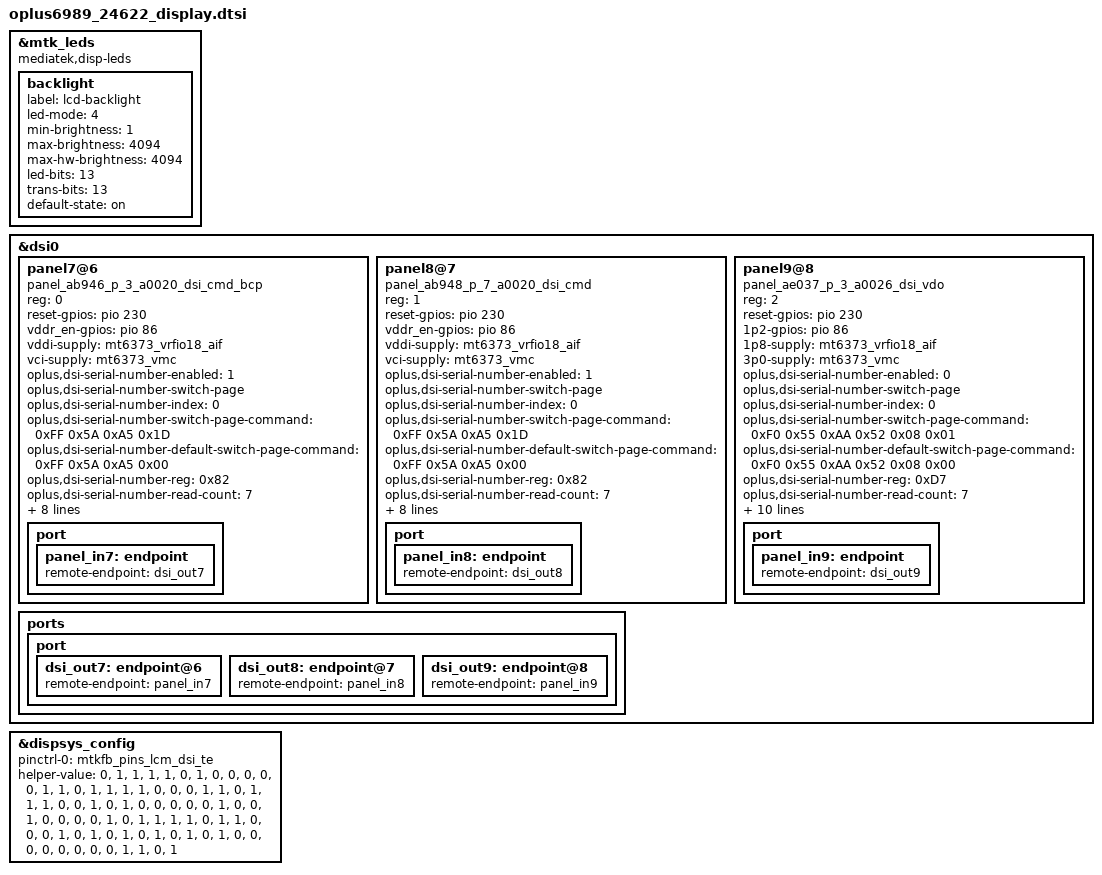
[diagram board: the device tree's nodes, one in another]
&mtk_leds {
	compatible = "mediatek,disp-leds";
	status = "okay";

	backlight {
		label = "lcd-backlight";
		led-mode = <4>;
		min-brightness = <1>;
		max-brightness = <4094>;
		max-hw-brightness = <4094>;
		led-bits = <13>;
		trans-bits = <13>;
		default-state = "on";
	};
};

&dsi0 {
	status = "okay";
	#address-cells = <1>;
	#size-cells = <0>;
	panel7@6 {
		compatible = "panel_ab946_p_3_a0020_dsi_cmd_bcp";
		reg = <0>;
		reset-gpios = <&pio 230 0>;
		vddr_en-gpios = <&pio 86 0>;
		vddi-supply = <&mt6373_vrfio18_aif>;
		vci-supply = <&mt6373_vmc>;
		oplus,dsi-serial-number-enabled=<1>;
		oplus,dsi-serial-number-switch-page;
		oplus,dsi-serial-number-index= <0>;
		oplus,dsi-serial-number-switch-page-command= <0xFF 0x5A 0xA5 0x1D>;
		oplus,dsi-serial-number-default-switch-page-command= <0xFF 0x5A 0xA5 0x00>;
		oplus,dsi-serial-number-reg= <0x82>;
		oplus,dsi-serial-number-read-count= <7>;
		/* 0 not support, 1 with switch, 2 Global high frequency pwm without switch */
		oplus,pwm-turbo-support = <2>;
		oplus,pwm-switch-backlight-threshold = <0x48A>;
		oplus,pwm-onepulse-support = <1>;
		oplus,pwm-onepulse-enabled = <0>;
		oplus-adfr-config = <0x201>;
		oplus-adfr-test-te-gpios = <&pio 222 0>;
		/* ofp config */
		oplus,ofp-fp-type = <0x10>;
		res-switch = <2>;
		pinctrl-names = "default";
		port {
			panel_in7: endpoint {
				remote-endpoint = <&dsi_out7>;
			};
		};
	};
	panel8@7 {
		compatible = "panel_ab948_p_7_a0020_dsi_cmd";
		reg = <1>;
		reset-gpios = <&pio 230 0>;
		vddr_en-gpios = <&pio 86 0>;
		vddi-supply = <&mt6373_vrfio18_aif>;
		vci-supply = <&mt6373_vmc>;
		oplus,dsi-serial-number-enabled=<1>;
		oplus,dsi-serial-number-switch-page;
		oplus,dsi-serial-number-index= <0>;
		oplus,dsi-serial-number-switch-page-command= <0xFF 0x5A 0xA5 0x1D>;
		oplus,dsi-serial-number-default-switch-page-command= <0xFF 0x5A 0xA5 0x00>;
		oplus,dsi-serial-number-reg= <0x82>;
		oplus,dsi-serial-number-read-count= <7>;
		/* 0 not support, 1 with switch, 2 Global high frequency pwm without switch */
		oplus,pwm-turbo-support = <2>;
		oplus,pwm-switch-backlight-threshold = <0x48A>;
		oplus,pwm-onepulse-support = <1>;
		oplus,pwm-onepulse-enabled = <0>;
		oplus-adfr-config = <0x201>;
		oplus-adfr-test-te-gpios = <&pio 222 0>;
		/* ofp config */
		oplus,ofp-fp-type = <0x10>;
		res-switch = <2>;
		pinctrl-names = "default";
		port {
			panel_in8: endpoint {
				remote-endpoint = <&dsi_out8>;
			};
		};
	};
	panel9@8 {
		compatible = "panel_ae037_p_3_a0026_dsi_vdo";
		reg = <2>;
		reset-gpios = <&pio 230 0>;
		1p2-gpios = <&pio 86 0>;
		1p8-supply = <&mt6373_vrfio18_aif>;
		3p0-supply = <&mt6373_vmc>;
		oplus,dsi-serial-number-enabled=<0>;
		oplus,dsi-serial-number-switch-page;
		oplus,dsi-serial-number-index= <0>;
		oplus,dsi-serial-number-switch-page-command= <0xF0 0x55 0xAA 0x52 0x08 0x01>;
		oplus,dsi-serial-number-default-switch-page-command= <0xF0 0x55 0xAA 0x52 0x08 0x00>;
		oplus,dsi-serial-number-reg= <0xD7>;
		oplus,dsi-serial-number-read-count= <7>;
		oplus,dsi-serial-number-year-offset = <0>;
		oplus,panel-max-brightness=<4094>;
		/* ofp config */
		oplus,ofp-fp-type = <0x210>;
		oplus,ofp-longrui-aod-config = <0x04>;
		oplus,ofp-fp-local-hbm-calibration;
		oplus,pwm-turbo-support = <1>;
		oplus,pwm-switch-backlight-threshold = <0x43F>;
		oplus,pwm-aid-switch-enable;
		oplus,pwm-onepulse-support = <1>;
		res-switch = <2>;
		pinctrl-names = "default";
		port {
			panel_in9: endpoint {
				remote-endpoint = <&dsi_out9>;
			};
		};
	};

	ports {
		port {
			dsi_out7: endpoint@6 {
				remote-endpoint = <&panel_in7>;
			};

			dsi_out8: endpoint@7 {
				remote-endpoint = <&panel_in8>;
			};

			dsi_out9: endpoint@8 {
				remote-endpoint = <&panel_in9>;
			};

		};
	};
};

&dispsys_config {
	pinctrl-names = "mode_te_te";
	pinctrl-0 = <&mtkfb_pins_lcm_dsi_te>;
	status = "okay";

	helper-value = <0>, /*MTK_DRM_OPT_STAGE*/
		<1>, /*MTK_DRM_OPT_USE_CMDQ*/
		<1>, /*MTK_DRM_OPT_USE_M4U*/
		<1>, /*MTK_DRM_OPT_MMQOS_SUPPORT*/
		<1>, /*MTK_DRM_OPT_MMDVFS_SUPPORT*/
		<0>, /*MTK_DRM_OPT_SODI_SUPPORT*/
		<1>, /*MTK_DRM_OPT_IDLE_MGR*/
		<0>, /*MTK_DRM_OPT_IDLEMGR_SWTCH_DECOUPLE*/
		<0>, /*MTK_DRM_OPT_IDLEMGR_BY_REPAINT*/
		<0>, /*MTK_DRM_OPT_IDLEMGR_ENTER_ULPS*/
		<0>, /*MTK_DRM_OPT_IDLEMGR_KEEP_LP11*/
		<0>, /*MTK_DRM_OPT_DYNAMIC_RDMA_GOLDEN_SETTING*/
		<1>, /*MTK_DRM_OPT_IDLEMGR_DISABLE_ROUTINE_IRQ*/
		<1>, /*MTK_DRM_OPT_IDLEMGR_ASYNC*/
		<0>, /*MTK_DRM_OPT_MET_LOG*/
		<1>, /*MTK_DRM_OPT_USE_PQ*/
		<1>, /*MTK_DRM_OPT_ESD_CHECK_RECOVERY*/
		<1>, /*MTK_DRM_OPT_ESD_CHECK_SWITCH*/
		<1>, /*MTK_DRM_OPT_PRESENT_FENCE*/
		<0>, /*MTK_DRM_OPT_RDMA_UNDERFLOW_AEE*/
		<0>, /*MTK_DRM_OPT_DSI_UNDERRUN_AEE*/
		<0>, /*MTK_DRM_OPT_ODDMR_UNDERRUN_AEE*/
		<1>, /*MTK_DRM_OPT_HRT*/
		<1>, /*MTK_DRM_OPT_HRT_MODE*/
		<0>, /*MTK_DRM_OPT_DELAYED_TRIGGER*/
		<1>, /*MTK_DRM_OPT_OVL_EXT_LAYER*/
		<1>, /*MTK_DRM_OPT_AOD*/
		<1>, /*MTK_DRM_OPT_RPO*/
		<0>, /*MTK_DRM_OPT_DUAL_PIPE*/
		<0>, /*MTK_DRM_OPT_DC_BY_HRT*/
		<1>, /*MTK_DRM_OPT_OVL_WCG*/
		<0>, /*MTK_DRM_OPT_OVL_SBCH*/
		<1>, /*MTK_DRM_OPT_COMMIT_NO_WAIT_VBLANK*/
		<0>, /*MTK_DRM_OPT_MET*/
		<0>, /*MTK_DRM_OPT_REG_PARSER_RAW_DUMP*/
		<0>, /*MTK_DRM_OPT_VP_PQ*/
		<0>, /*MTK_DRM_OPT_GAME_PQ*/
		<0>, /*MTK_DRM_OPT_MMPATH*/
		<1>, /*MTK_DRM_OPT_HBM*/
		<0>, /*MTK_DRM_OPT_VDS_PATH_SWITCH*/
		<0>, /*MTK_DRM_OPT_LAYER_REC*/
		<1>, /*MTK_DRM_OPT_CLEAR_LAYER*/
		<0>, /*MTK_DRM_OPT_LFR*/
		<0>, /*MTK_DRM_OPT_SF_PF*/
		<0>, /*MTK_DRM_OPT_DYN_MIPI_CHANGE*/
		<0>, /*MTK_DRM_OPT_PRIM_DUAL_PIPE*/
		<1>, /*MTK_DRM_OPT_MSYNC2_0*/
		<0>, /*MTK_DRM_OPT_MSYNC2_0_WAIT_EPT*/
		<1>, /*MTK_DRM_OPT_MML_PRIMARY*/
		<1>, /*MTK_DRM_OPT_MML_SUPPORT_CMD_MODE*/
		<1>, /*MTK_DRM_OPT_MML_PQ*/
		<1>, /*MTK_DRM_OPT_MML_IR*/
		<0>, /*MTK_DRM_OPT_DUAL_TE*/
		<1>, /*MTK_DRM_OPT_RES_SWITCH*/
		<1>, /*MTK_DRM_OPT_RES_SWITCH_ON_AP*/
		<0>, /*MTK_DRM_OPT_PREFETCH_TE*/
		<0>, /*MTK_DRM_OPT_VIDLE_APSRC_OFF*/
		<0>, /*MTK_DRM_OPT_VIDLE_DSI_PLL_OFF*/
		<1>, /*MTK_DRM_OPT_CHECK_TRIGGER_MERGE*/
		<0>, /*MTK_DRM_OPT_VIRTUAL_DISP*/
		<1>, /*MTK_DRM_OPT_OVL_BW_MONITOR*/
		<0>, /*MTK_DRM_OPT_GPU_CACHE*/
		<1>, /*MTK_DRM_OPT_SPHRT*/
		<0>, /*MTK_DRM_OPT_SDPA_OVL_SWITCH*/
		<1>, /*MTK_DRM_OPT_HRT_BY_LARB*/
		<0>, /*MTK_DRM_OPT_TILE_OVERHEAD*/
		<1>, /*MTK_DRM_OPT_VIDLE_TOP_EN*/
		<0>, /*MTK_DRM_OPT_VIDLE_MTCMOS_DT_EN*/
		<1>, /*MTK_DRM_OPT_VIDLE_MMINFRA_DT_EN*/
		<0>, /*MTK_DRM_OPT_VIDLE_DVFS_DT_EN*/
		<0>, /*MTK_DRM_OPT_VIDLE_QOS_DT_EN*/
		<0>, /*MTK_DRM_OPT_VIDLE_GCE_TS_EN*/
		<0>, /*MTK_DRM_OPT_VIDLE_DECOUPLE_MODE*/
		<0>, /*MTK_DRM_OPT_VIDLE_VDO_PANEL*/
		<0>, /*MTK_DRM_OPT_VIDLE_HOME_SCREEN_IDLE*/
		<0>, /*MTK_DRM_OPT_DPC_PRE_TE_EN*/
		<0>, /*MTK_DRM_OPT_PARTIAL_UPDATE*/
		<1>, /*MTK_DRM_OPT_SLC_ALL_CACHE*/
		<1>, /*MTK_DRM_OPT_OVL_WCG_BY_COLOR_MODE*/
		<0>, /*"MTK_DRM_OPT_OVLSYS_CASCADE"*/
		<1>; /*"MTK_DRM_OPT_PER_LARB_PORT_PEAK"*/
};
